AUTOSAR XML (schema 4-2-2)
package /STELLANTIS/EPT/ASWCs
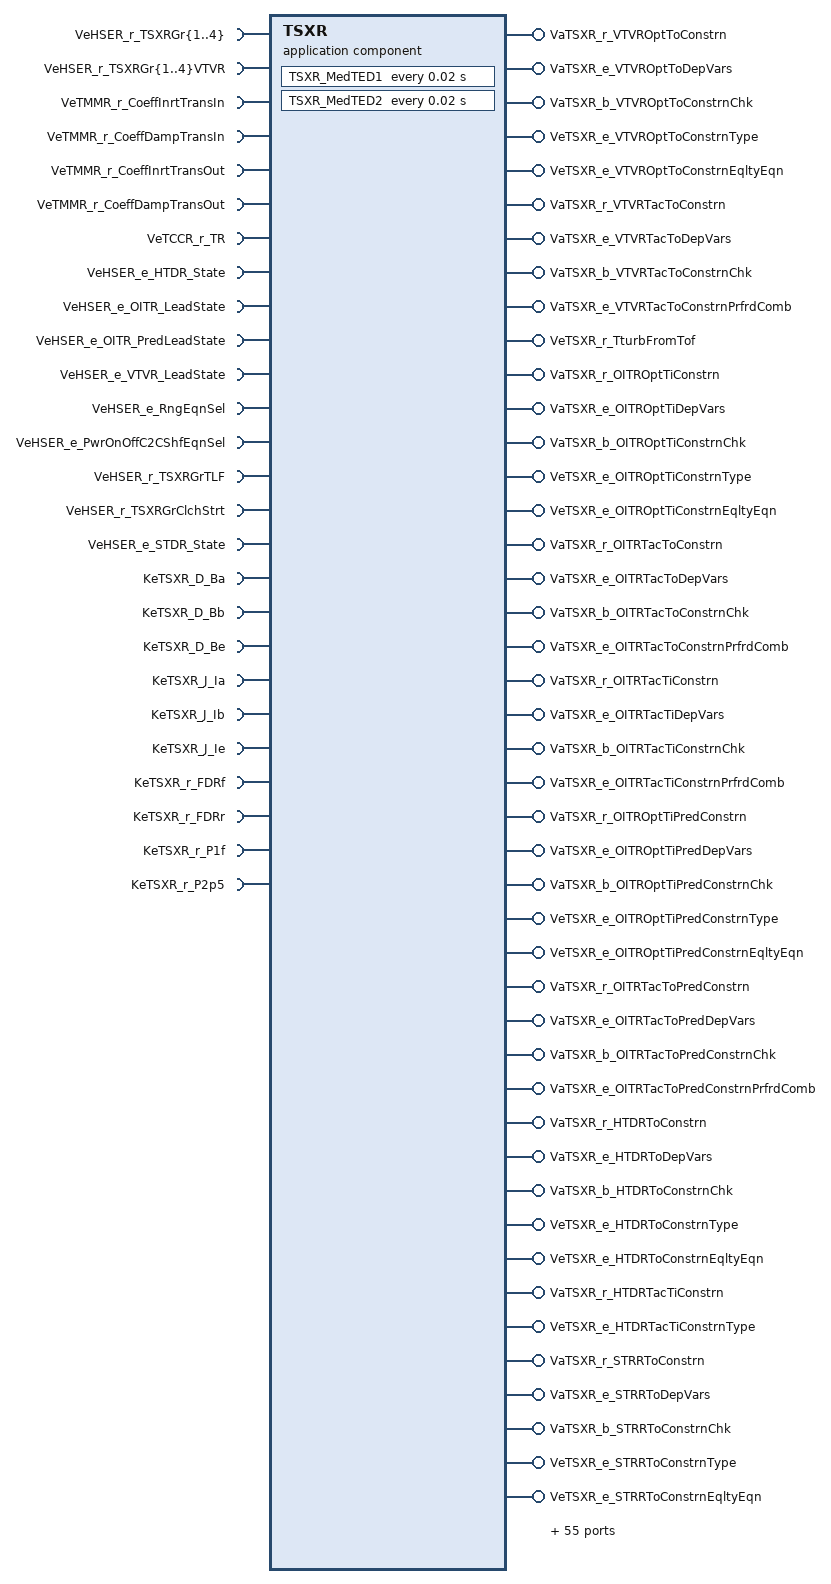
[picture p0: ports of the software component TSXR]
  application sw component type TSXR
    22 x require port:
      VeHSER_r_TSXRGr{1..4}: nonqueued-receiver-com-spec{data-element=Value, init-value=0}, required-interface=VeHSER_r_TSXRGr{1..4}
      VeHSER_r_TSXRGr{1..4}VTVR: nonqueued-receiver-com-spec{data-element=Value, init-value=0}, required-interface=VeHSER_r_TSXRGr{1..4}VTVR
      VeTMMR_r_CoeffInrtTransIn: nonqueued-receiver-com-spec{data-element=Value, init-value=0}, required-interface=VeTMMR_r_CoeffInrtTransIn
      VeTMMR_r_CoeffDampTransIn: nonqueued-receiver-com-spec{data-element=Value, init-value=0}, required-interface=VeTMMR_r_CoeffDampTransIn
      VeTMMR_r_CoeffInrtTransOut: nonqueued-receiver-com-spec{data-element=Value, init-value=0}, required-interface=VeTMMR_r_CoeffInrtTransOut
      VeTMMR_r_CoeffDampTransOut: nonqueued-receiver-com-spec{data-element=Value, init-value=0}, required-interface=VeTMMR_r_CoeffDampTransOut
      VeTCCR_r_TR: nonqueued-receiver-com-spec{data-element=Value, init-value=0}, required-interface=VeTCCR_r_TR
      VeHSER_e_HTDR_State: nonqueued-receiver-com-spec{data-element=Value, init-value=CeHSER_e_Neut_State}, required-interface=VeHSER_e_HTDR_State
      VeHSER_e_OITR_LeadState: nonqueued-receiver-com-spec{data-element=Value, init-value=CeHSER_e_Neut_State}, required-interface=VeHSER_e_OITR_LeadState
      VeHSER_e_OITR_PredLeadState: nonqueued-receiver-com-spec{data-element=Value, init-value=CeHSER_e_Neut_State}, required-interface=VeHSER_e_OITR_PredLeadState
      VeHSER_e_VTVR_LeadState: nonqueued-receiver-com-spec{data-element=Value, init-value=CeHSER_e_Neut_State}, required-interface=VeHSER_e_VTVR_LeadState
      VeHSER_e_RngEqnSel: nonqueued-receiver-com-spec{data-element=Value, init-value=CeHSER_e_UseNeutralEqn}, required-interface=VeHSER_e_RngEqnSel
      VeHSER_e_PwrOnOffC2CShfEqnSel: nonqueued-receiver-com-spec{data-element=Value, init-value=CeHSER_e_UseNeutralEqn}, required-interface=VeHSER_e_PwrOnOffC2CShfEqnSel
      VeHSER_r_TSXRGrTLF: nonqueued-receiver-com-spec{data-element=Value, init-value=0}, required-interface=VeHSER_r_TSXRGrTLF
      VeHSER_r_TSXRGrClchStrt: nonqueued-receiver-com-spec{data-element=Value, init-value=0}, required-interface=VeHSER_r_TSXRGrClchStrt
      VeHSER_e_STDR_State: nonqueued-receiver-com-spec{data-element=Value, init-value=CeHSER_e_Neut_State}, required-interface=VeHSER_e_STDR_State
    99 x provide port:
      VaTSXR_r_VTVROptToConstrn: nonqueued-sender-com-spec{data-element=Value, init-value=114 x 0}, provided-interface=VaTSXR_r_VTVROptToConstrn
      VaTSXR_e_VTVROptToDepVars: nonqueued-sender-com-spec{data-element=Value, init-value=6 x CeTSXR_e_Ta}, provided-interface=VaTSXR_e_VTVROptToDepVars
      VaTSXR_b_VTVROptToConstrnChk: nonqueued-sender-com-spec{data-element=Value, init-value=6 x 0}, provided-interface=VaTSXR_b_VTVROptToConstrnChk
      VeTSXR_e_VTVROptToConstrnType: nonqueued-sender-com-spec{data-element=Value, init-value=CeTSXR_e_Mode}, provided-interface=VeTSXR_e_VTVROptToConstrnType
      VeTSXR_e_VTVROptToConstrnEqltyEqn: nonqueued-sender-com-spec{data-element=Value, init-value=CeTSXR_e_Second}, provided-interface=VeTSXR_e_VTVROptToConstrnEqltyEqn
      VaTSXR_r_VTVRTacToConstrn: nonqueued-sender-com-spec{data-element=Value, init-value=114 x 0}, provided-interface=VaTSXR_r_VTVRTacToConstrn
      VaTSXR_e_VTVRTacToDepVars: nonqueued-sender-com-spec{data-element=Value, init-value=6 x CeTSXR_e_Ta}, provided-interface=VaTSXR_e_VTVRTacToDepVars
      VaTSXR_b_VTVRTacToConstrnChk: nonqueued-sender-com-spec{data-element=Value, init-value=6 x 0}, provided-interface=VaTSXR_b_VTVRTacToConstrnChk
      VaTSXR_e_VTVRTacToConstrnPrfrdComb: nonqueued-sender-com-spec{data-element=Value, init-value=10 x CeTSXR_e_NoComb}, provided-interface=VaTSXR_e_VTVRTacToConstrnPrfrdComb
      VeTSXR_r_TturbFromTof: nonqueued-sender-com-spec{data-element=Value, init-value=0}, provided-interface=VeTSXR_r_TturbFromTof
      VaTSXR_r_OITROptTiConstrn: nonqueued-sender-com-spec{data-element=Value, init-value=114 x 0}, provided-interface=VaTSXR_r_OITROptTiConstrn
      VaTSXR_e_OITROptTiDepVars: nonqueued-sender-com-spec{data-element=Value, init-value=6 x CeTSXR_e_Ta}, provided-interface=VaTSXR_e_OITROptTiDepVars
      VaTSXR_b_OITROptTiConstrnChk: nonqueued-sender-com-spec{data-element=Value, init-value=6 x 0}, provided-interface=VaTSXR_b_OITROptTiConstrnChk
      VeTSXR_e_OITROptTiConstrnType: nonqueued-sender-com-spec{data-element=Value, init-value=CeTSXR_e_Mode}, provided-interface=VeTSXR_e_OITROptTiConstrnType
      VeTSXR_e_OITROptTiConstrnEqltyEqn: nonqueued-sender-com-spec{data-element=Value, init-value=CeTSXR_e_Second}, provided-interface=VeTSXR_e_OITROptTiConstrnEqltyEqn
      VaTSXR_r_OITRTacToConstrn: nonqueued-sender-com-spec{data-element=Value, init-value=114 x 0}, provided-interface=VaTSXR_r_OITRTacToConstrn
      VaTSXR_e_OITRTacToDepVars: nonqueued-sender-com-spec{data-element=Value, init-value=6 x CeTSXR_e_Ta}, provided-interface=VaTSXR_e_OITRTacToDepVars
      VaTSXR_b_OITRTacToConstrnChk: nonqueued-sender-com-spec{data-element=Value, init-value=6 x 0}, provided-interface=VaTSXR_b_OITRTacToConstrnChk
      VaTSXR_e_OITRTacToConstrnPrfrdComb: nonqueued-sender-com-spec{data-element=Value, init-value=10 x CeTSXR_e_NoComb}, provided-interface=VaTSXR_e_OITRTacToConstrnPrfrdComb
      VaTSXR_r_OITRTacTiConstrn: nonqueued-sender-com-spec{data-element=Value, init-value=114 x 0}, provided-interface=VaTSXR_r_OITRTacTiConstrn
      VaTSXR_e_OITRTacTiDepVars: nonqueued-sender-com-spec{data-element=Value, init-value=6 x CeTSXR_e_Ta}, provided-interface=VaTSXR_e_OITRTacTiDepVars
      VaTSXR_b_OITRTacTiConstrnChk: nonqueued-sender-com-spec{data-element=Value, init-value=6 x 0}, provided-interface=VaTSXR_b_OITRTacTiConstrnChk
      VaTSXR_e_OITRTacTiConstrnPrfrdComb: nonqueued-sender-com-spec{data-element=Value, init-value=10 x CeTSXR_e_NoComb}, provided-interface=VaTSXR_e_OITRTacTiConstrnPrfrdComb
      VaTSXR_r_OITROptTiPredConstrn: nonqueued-sender-com-spec{data-element=Value, init-value=114 x 0}, provided-interface=VaTSXR_r_OITROptTiPredConstrn
      VaTSXR_e_OITROptTiPredDepVars: nonqueued-sender-com-spec{data-element=Value, init-value=6 x CeTSXR_e_Ta}, provided-interface=VaTSXR_e_OITROptTiPredDepVars
      VaTSXR_b_OITROptTiPredConstrnChk: nonqueued-sender-com-spec{data-element=Value, init-value=6 x 0}, provided-interface=VaTSXR_b_OITROptTiPredConstrnChk
      VeTSXR_e_OITROptTiPredConstrnType: nonqueued-sender-com-spec{data-element=Value, init-value=CeTSXR_e_Mode}, provided-interface=VeTSXR_e_OITROptTiPredConstrnType
      VeTSXR_e_OITROptTiPredConstrnEqltyEqn: nonqueued-sender-com-spec{data-element=Value, init-value=CeTSXR_e_Second}, provided-interface=VeTSXR_e_OITROptTiPredConstrnEqltyEqn
      VaTSXR_r_OITRTacToPredConstrn: nonqueued-sender-com-spec{data-element=Value, init-value=114 x 0}, provided-interface=VaTSXR_r_OITRTacToPredConstrn
      VaTSXR_e_OITRTacToPredDepVars: nonqueued-sender-com-spec{data-element=Value, init-value=6 x CeTSXR_e_Ta}, provided-interface=VaTSXR_e_OITRTacToPredDepVars
      VaTSXR_b_OITRTacToPredConstrnChk: nonqueued-sender-com-spec{data-element=Value, init-value=6 x 0}, provided-interface=VaTSXR_b_OITRTacToPredConstrnChk
      VaTSXR_e_OITRTacToPredConstrnPrfrdComb: nonqueued-sender-com-spec{data-element=Value, init-value=10 x CeTSXR_e_NoComb}, provided-interface=VaTSXR_e_OITRTacToPredConstrnPrfrdComb
      VaTSXR_r_HTDRToConstrn: nonqueued-sender-com-spec{data-element=Value, init-value=114 x 0}, provided-interface=VaTSXR_r_HTDRToConstrn
      VaTSXR_e_HTDRToDepVars: nonqueued-sender-com-spec{data-element=Value, init-value=6 x CeTSXR_e_Ta}, provided-interface=VaTSXR_e_HTDRToDepVars
      VaTSXR_b_HTDRToConstrnChk: nonqueued-sender-com-spec{data-element=Value, init-value=6 x 0}, provided-interface=VaTSXR_b_HTDRToConstrnChk
      VeTSXR_e_HTDRToConstrnType: nonqueued-sender-com-spec{data-element=Value, init-value=CeTSXR_e_Mode}, provided-interface=VeTSXR_e_HTDRToConstrnType
      VeTSXR_e_HTDRToConstrnEqltyEqn: nonqueued-sender-com-spec{data-element=Value, init-value=CeTSXR_e_Second}, provided-interface=VeTSXR_e_HTDRToConstrnEqltyEqn
      VaTSXR_r_HTDRTacTiConstrn: nonqueued-sender-com-spec{data-element=Value, init-value=114 x 0}, provided-interface=VaTSXR_r_HTDRTacTiConstrn
      VeTSXR_e_HTDRTacTiConstrnType: nonqueued-sender-com-spec{data-element=Value, init-value=CeTSXR_e_Mode}, provided-interface=VeTSXR_e_HTDRTacTiConstrnType
      VaTSXR_r_STRRToConstrn: nonqueued-sender-com-spec{data-element=Value, init-value=114 x 0}, provided-interface=VaTSXR_r_STRRToConstrn
      VaTSXR_e_STRRToDepVars: nonqueued-sender-com-spec{data-element=Value, init-value=6 x CeTSXR_e_Ta}, provided-interface=VaTSXR_e_STRRToDepVars
      VaTSXR_b_STRRToConstrnChk: nonqueued-sender-com-spec{data-element=Value, init-value=6 x 0}, provided-interface=VaTSXR_b_STRRToConstrnChk
      VeTSXR_e_STRRToConstrnType: nonqueued-sender-com-spec{data-element=Value, init-value=CeTSXR_e_Mode}, provided-interface=VeTSXR_e_STRRToConstrnType
      VeTSXR_e_STRRToConstrnEqltyEqn: nonqueued-sender-com-spec{data-element=Value, init-value=CeTSXR_e_Second}, provided-interface=VeTSXR_e_STRRToConstrnEqltyEqn
      VaTSXR_r_HSERNidotConstrn: nonqueued-sender-com-spec{data-element=Value, init-value=114 x 0}, provided-interface=VaTSXR_r_HSERNidotConstrn
      VaTSXR_e_HSERNidotDepVars: nonqueued-sender-com-spec{data-element=Value, init-value=6 x CeTSXR_e_Ta}, provided-interface=VaTSXR_e_HSERNidotDepVars
      VaTSXR_b_HSERNidotConstrnChk: nonqueued-sender-com-spec{data-element=Value, init-value=6 x 0}, provided-interface=VaTSXR_b_HSERNidotConstrnChk
      VaTSXR_e_HSERNidotConstrnPrfrdComb: nonqueued-sender-com-spec{data-element=Value, init-value=10 x CeTSXR_e_NoComb}, provided-interface=VaTSXR_e_HSERNidotConstrnPrfrdComb
      VaTSXR_r_HSERNxDotCnstrnt: nonqueued-sender-com-spec{data-element=Value, init-value=114 x 0}, provided-interface=VaTSXR_r_HSERNxDotCnstrnt
      VaTSXR_e_HSERNxDotDepVars: nonqueued-sender-com-spec{data-element=Value, init-value=6 x CeTSXR_e_Ta}, provided-interface=VaTSXR_e_HSERNxDotDepVars
      VaTSXR_b_HSERNxDotChk: nonqueued-sender-com-spec{data-element=Value, init-value=6 x 0}, provided-interface=VaTSXR_b_HSERNxDotChk
      VaTSXR_e_HSERNxdotConstrnPrfrdComb: nonqueued-sender-com-spec{data-element=Value, init-value=10 x CeTSXR_e_NoComb}, provided-interface=VaTSXR_e_HSERNxdotConstrnPrfrdComb
      VaTSXR_r_HSERTcyFromTcxAndTi_TaTbDep: nonqueued-sender-com-spec{data-element=Value, init-value=[0, 0]}, provided-interface=VaTSXR_r_HSERTcyFromTcxAndTi_TaTbDep
      VaTSXR_r_AXLRCalcToEqn: nonqueued-sender-com-spec{data-element=Value, init-value=19 x 0}, provided-interface=VaTSXR_r_AXLRCalcToEqn
      VaTSXR_r_TITRCalcTiEqn: nonqueued-sender-com-spec{data-element=Value, init-value=19 x 0}, provided-interface=VaTSXR_r_TITRCalcTiEqn
      VaTSXR_r_HSERNiMat: nonqueued-sender-com-spec{data-element=Value, init-value=36 x 0}, provided-interface=VaTSXR_r_HSERNiMat
      VaTSXR_b_HSERNiMatChk: nonqueued-sender-com-spec{data-element=Value, init-value=[0, 0, 0, 0]}, provided-interface=VaTSXR_b_HSERNiMatChk
      VaTSXR_b_HSERNiMatActSpdFlag: nonqueued-sender-com-spec{data-element=Value, init-value=9 x 0}, provided-interface=VaTSXR_b_HSERNiMatActSpdFlag
      VaTSXR_r_HSERNoMat: nonqueued-sender-com-spec{data-element=Value, init-value=36 x 0}, provided-interface=VaTSXR_r_HSERNoMat
      VaTSXR_b_HSERNoMatChk: nonqueued-sender-com-spec{data-element=Value, init-value=[0, 0, 0, 0]}, provided-interface=VaTSXR_b_HSERNoMatChk
      VaTSXR_b_HSERNoMatActSpdFlag: nonqueued-sender-com-spec{data-element=Value, init-value=9 x 0}, provided-interface=VaTSXR_b_HSERNoMatActSpdFlag
      VaTSXR_r_STDRMotSpdMat_NmDep: nonqueued-sender-com-spec{data-element=Value, init-value=9 x 0}, provided-interface=VaTSXR_r_STDRMotSpdMat_NmDep
      VaTSXR_r_OITRMotSpdMat_NmDep: nonqueued-sender-com-spec{data-element=Value, init-value=9 x 0}, provided-interface=VaTSXR_r_OITRMotSpdMat_NmDep
      VaTSXR_r_VTVRMotSpdMat_NmDep: nonqueued-sender-com-spec{data-element=Value, init-value=9 x 0}, provided-interface=VaTSXR_r_VTVRMotSpdMat_NmDep
      VaTSXR_r_N_ClchSlpMat_NcnDep: nonqueued-sender-com-spec{data-element=Value, init-value=32 x 0}, provided-interface=VaTSXR_r_N_ClchSlpMat_NcnDep
      VaTSXR_r_M1_ClchSlpMat_NcnDep: nonqueued-sender-com-spec{data-element=Value, init-value=32 x 0}, provided-interface=VaTSXR_r_M1_ClchSlpMat_NcnDep
      VaTSXR_r_M2_ClchSlpMat_NcnDep: nonqueued-sender-com-spec{data-element=Value, init-value=32 x 0}, provided-interface=VaTSXR_r_M2_ClchSlpMat_NcnDep
      VaTSXR_r_GearRatios: nonqueued-sender-com-spec{data-element=Value, init-value=[0, 0, 0, 0]}, provided-interface=VaTSXR_r_GearRatios
      VaTSXR_r_M_CalcTCxEqn: nonqueued-sender-com-spec{data-element=Value, init-value=76 x 0}, provided-interface=VaTSXR_r_M_CalcTCxEqn
      VaTSXR_r_CalcTlfEqn: nonqueued-sender-com-spec{data-element=Value, init-value=19 x 0}, provided-interface=VaTSXR_r_CalcTlfEqn
      VaTSXR_r_STRRNxMat_NcnDep: nonqueued-sender-com-spec{data-element=Value, init-value=6 x 0}, provided-interface=VaTSXR_r_STRRNxMat_NcnDep
      VaTSXR_r_HSERNxMat: nonqueued-sender-com-spec{data-element=Value, init-value=36 x 0}, provided-interface=VaTSXR_r_HSERNxMat
      VaTSXR_b_HSERNxMatChk: nonqueued-sender-com-spec{data-element=Value, init-value=[0, 0, 0, 0]}, provided-interface=VaTSXR_b_HSERNxMatChk
      VaTSXR_b_HSERNxMatActSpdFlag: nonqueued-sender-com-spec{data-element=Value, init-value=9 x 0}, provided-interface=VaTSXR_b_HSERNxMatActSpdFlag
      VaTSXR_r_HSERNxNc1IndDep: nonqueued-sender-com-spec{data-element=Value, init-value=12 x 0}, provided-interface=VaTSXR_r_HSERNxNc1IndDep
      VaTSXR_r_HSERNxNc2IndDep: nonqueued-sender-com-spec{data-element=Value, init-value=12 x 0}, provided-interface=VaTSXR_r_HSERNxNc2IndDep
      VaTSXR_r_HSERNxNMtrIndDep: nonqueued-sender-com-spec{data-element=Value, init-value=12 x 0}, provided-interface=VaTSXR_r_HSERNxNMtrIndDep
      VeTSXR_r_NoDot2NxDot: nonqueued-sender-com-spec{data-element=Value, init-value=0}, provided-interface=VeTSXR_r_NoDot2NxDot
      VeTSXR_e_VTVRTacToConstrnCombEqn: nonqueued-sender-com-spec{data-element=Value, init-value=CeTSXR_e_Second}, provided-interface=VeTSXR_e_VTVRTacToConstrnCombEqn
      VeTSXR_e_OITRTacTiConstrnCombEqn: nonqueued-sender-com-spec{data-element=Value, init-value=CeTSXR_e_Second}, provided-interface=VeTSXR_e_OITRTacTiConstrnCombEqn
      VeTSXR_e_HSERNidotConstrnCombEqn: nonqueued-sender-com-spec{data-element=Value, init-value=CeTSXR_e_Second}, provided-interface=VeTSXR_e_HSERNidotConstrnCombEqn
      VeTSXR_e_OITRTacToPredConstrnCombEqn: nonqueued-sender-com-spec{data-element=Value, init-value=CeTSXR_e_Second}, provided-interface=VeTSXR_e_OITRTacToPredConstrnCombEqn
      VeTSXR_e_OITRTacToConstrnCombEqn: nonqueued-sender-com-spec{data-element=Value, init-value=CeTSXR_e_Second}, provided-interface=VeTSXR_e_OITRTacToConstrnCombEqn
      VeTSXR_e_HSERNxdotConstrnCombEqn: nonqueued-sender-com-spec{data-element=Value, init-value=CeTSXR_e_Second}, provided-interface=VeTSXR_e_HSERNxdotConstrnCombEqn
      VaTSXR_r_AXLRCalcTofEqn: nonqueued-sender-com-spec{data-element=Value, init-value=19 x 0}, provided-interface=VaTSXR_r_AXLRCalcTofEqn
      VaTSXR_r_AXLRCalcTorEqn: nonqueued-sender-com-spec{data-element=Value, init-value=19 x 0}, provided-interface=VaTSXR_r_AXLRCalcTorEqn
      VaTSXR_b_VTVRToConstrnPalChk: nonqueued-sender-com-spec{data-element=Value, init-value=6 x 0}, provided-interface=VaTSXR_b_VTVRToConstrnPalChk
      VaTSXR_b_OITRTacToPredConstrnPalChk: nonqueued-sender-com-spec{data-element=Value, init-value=6 x 0}, provided-interface=VaTSXR_b_OITRTacToPredConstrnPalChk
      VaTSXR_b_OITRTacToConstrnPalChk: nonqueued-sender-com-spec{data-element=Value, init-value=6 x 0}, provided-interface=VaTSXR_b_OITRTacToConstrnPalChk
      VaTSXR_b_OITRTacTiConstrnPalChk: nonqueued-sender-com-spec{data-element=Value, init-value=6 x 0}, provided-interface=VaTSXR_b_OITRTacTiConstrnPalChk
      VaTSXR_b_HTDRTacTiConstrnPalChk: nonqueued-sender-com-spec{data-element=Value, init-value=6 x 0}, provided-interface=VaTSXR_b_HTDRTacTiConstrnPalChk
      VaTSXR_b_HSERNidotConstrnPalChk: nonqueued-sender-com-spec{data-element=Value, init-value=6 x 0}, provided-interface=VaTSXR_b_HSERNidotConstrnPalChk
      VaTSXR_b_HSERNxdotConstrnPalChk: nonqueued-sender-com-spec{data-element=Value, init-value=6 x 0}, provided-interface=VaTSXR_b_HSERNxdotConstrnPalChk
      VaTSXR_r_OITRTacTiPredConstrn: nonqueued-sender-com-spec{data-element=Value, init-value=114 x 0}, provided-interface=VaTSXR_r_OITRTacTiPredConstrn
      VaTSXR_e_OITRTacTiPredDepVars: nonqueued-sender-com-spec{data-element=Value, init-value=6 x CeTSXR_e_Ta}, provided-interface=VaTSXR_e_OITRTacTiPredDepVars
      VaTSXR_b_OITRTacTiPredConstrnChk: nonqueued-sender-com-spec{data-element=Value, init-value=6 x 0}, provided-interface=VaTSXR_b_OITRTacTiPredConstrnChk
      VaTSXR_e_OITRTacTiPredConstrnPrfrdComb: nonqueued-sender-com-spec{data-element=Value, init-value=10 x CeTSXR_e_NoComb}, provided-interface=VaTSXR_e_OITRTacTiPredConstrnPrfrdComb
      VeTSXR_e_OITRTacTiPredConstrnCombEqn: nonqueued-sender-com-spec{data-element=Value, init-value=CeTSXR_e_Second}, provided-interface=VeTSXR_e_OITRTacTiPredConstrnCombEqn
      VaTSXR_b_OITRTacTiPredConstrnPalChk: nonqueued-sender-com-spec{data-element=Value, init-value=6 x 0}, provided-interface=VaTSXR_b_OITRTacTiPredConstrnPalChk
    10 x require port:
      KeTSXR_D_Ba: parameter-require-com-spec{init-value=KeTSXR_D_Ba_KeTSXR_D_Ba:0.000165328965522349, parameter=KeTSXR_D_Ba}, required-interface=KeTSXR_D_Ba
      KeTSXR_D_Bb: parameter-require-com-spec{init-value=KeTSXR_D_Bb_KeTSXR_D_Bb:5.01592949149199E-05, parameter=KeTSXR_D_Bb}, required-interface=KeTSXR_D_Bb
      KeTSXR_D_Be: parameter-require-com-spec{init-value=KeTSXR_D_Be_KeTSXR_D_Be:0.00143155723344535, parameter=KeTSXR_D_Be}, required-interface=KeTSXR_D_Be
      KeTSXR_J_Ia: parameter-require-com-spec{init-value=KeTSXR_J_Ia_KeTSXR_J_Ia:0.00136836851015687, parameter=KeTSXR_J_Ia}, required-interface=KeTSXR_J_Ia
      KeTSXR_J_Ib: parameter-require-com-spec{init-value=KeTSXR_J_Ib_KeTSXR_J_Ib:0.0059690261259675026, parameter=KeTSXR_J_Ib}, required-interface=KeTSXR_J_Ib
      KeTSXR_J_Ie: parameter-require-com-spec{init-value=KeTSXR_J_Ie_KeTSXR_J_Ie:0.0124616511166096, parameter=KeTSXR_J_Ie}, required-interface=KeTSXR_J_Ie
      KeTSXR_r_FDRf: parameter-require-com-spec{init-value=KeTSXR_r_FDRf_KeTSXR_r_FDRf:3.58823537826538, parameter=KeTSXR_r_FDRf}, required-interface=KeTSXR_r_FDRf
      KeTSXR_r_FDRr: parameter-require-com-spec{init-value=KeTSXR_r_FDRr_KeTSXR_r_FDRr:11.1999998092651, parameter=KeTSXR_r_FDRr}, required-interface=KeTSXR_r_FDRr
      KeTSXR_r_P1f: parameter-require-com-spec{init-value=KeTSXR_r_P1f_KeTSXR_r_P1f:2.55550003051758, parameter=KeTSXR_r_P1f}, required-interface=KeTSXR_r_P1f
      KeTSXR_r_P2p5: parameter-require-com-spec{init-value=KeTSXR_r_P2p5_KeTSXR_r_P2p5:2.5, parameter=KeTSXR_r_P2p5}, required-interface=KeTSXR_r_P2p5
    behavior IB_TSXR: data-type-mapping=msADTtoIDTMapping, handle-termination-and-restart=NO-SUPPORT
      timing event Event_MedTED1: start-on-event=TSXR_MedTED1, period=0.02
      timing event Event_MedTED2: start-on-event=TSXR_MedTED2, period=0.02
      init event Event_TSXR_ac_Init: start-on-event=TSXR_ac_Init
      init event Event_PwrOn: start-on-event=TSXR_PwrOn
      4 x runnable:
        TSXR_ac_Init
          data-send-points:
            97 x access:
              OUT_VaTSXR_r_VTVROptToConstrn_Value: accessed-variable=VaTSXR_r_VTVROptToConstrn.Value
              OUT_VaTSXR_e_VTVROptToDepVars_Value: accessed-variable=VaTSXR_e_VTVROptToDepVars.Value
              OUT_VaTSXR_b_VTVROptToConstrnChk_Value: accessed-variable=VaTSXR_b_VTVROptToConstrnChk.Value
              OUT_VeTSXR_e_VTVROptToConstrnType_Value: accessed-variable=VeTSXR_e_VTVROptToConstrnType.Value
              OUT_VeTSXR_e_VTVROptToConstrnEqltyEqn_Value: accessed-variable=VeTSXR_e_VTVROptToConstrnEqltyEqn.Value
              OUT_VaTSXR_r_VTVRTacToConstrn_Value: accessed-variable=VaTSXR_r_VTVRTacToConstrn.Value
              OUT_VaTSXR_e_VTVRTacToDepVars_Value: accessed-variable=VaTSXR_e_VTVRTacToDepVars.Value
              OUT_VaTSXR_b_VTVRTacToConstrnChk_Value: accessed-variable=VaTSXR_b_VTVRTacToConstrnChk.Value
              OUT_VaTSXR_e_VTVRTacToConstrnPrfrdComb_Value: accessed-variable=VaTSXR_e_VTVRTacToConstrnPrfrdComb.Value
              OUT_VaTSXR_r_OITROptTiConstrn_Value: accessed-variable=VaTSXR_r_OITROptTiConstrn.Value
              OUT_VaTSXR_e_OITROptTiDepVars_Value: accessed-variable=VaTSXR_e_OITROptTiDepVars.Value
              OUT_VaTSXR_b_OITROptTiConstrnChk_Value: accessed-variable=VaTSXR_b_OITROptTiConstrnChk.Value
              OUT_VeTSXR_e_OITROptTiConstrnType_Value: accessed-variable=VeTSXR_e_OITROptTiConstrnType.Value
              OUT_VeTSXR_e_OITROptTiConstrnEqltyEqn_Value: accessed-variable=VeTSXR_e_OITROptTiConstrnEqltyEqn.Value
              OUT_VaTSXR_r_OITRTacToConstrn_Value: accessed-variable=VaTSXR_r_OITRTacToConstrn.Value
              OUT_VaTSXR_e_OITRTacToDepVars_Value: accessed-variable=VaTSXR_e_OITRTacToDepVars.Value
              OUT_VaTSXR_b_OITRTacToConstrnChk_Value: accessed-variable=VaTSXR_b_OITRTacToConstrnChk.Value
              OUT_VaTSXR_e_OITRTacToConstrnPrfrdComb_Value: accessed-variable=VaTSXR_e_OITRTacToConstrnPrfrdComb.Value
              OUT_VaTSXR_r_OITRTacTiConstrn_Value: accessed-variable=VaTSXR_r_OITRTacTiConstrn.Value
              OUT_VaTSXR_e_OITRTacTiDepVars_Value: accessed-variable=VaTSXR_e_OITRTacTiDepVars.Value
              OUT_VaTSXR_b_OITRTacTiConstrnChk_Value: accessed-variable=VaTSXR_b_OITRTacTiConstrnChk.Value
              OUT_VaTSXR_e_OITRTacTiConstrnPrfrdComb_Value: accessed-variable=VaTSXR_e_OITRTacTiConstrnPrfrdComb.Value
              OUT_VaTSXR_r_OITROptTiPredConstrn_Value: accessed-variable=VaTSXR_r_OITROptTiPredConstrn.Value
              OUT_VaTSXR_e_OITROptTiPredDepVars_Value: accessed-variable=VaTSXR_e_OITROptTiPredDepVars.Value
              OUT_VaTSXR_b_OITROptTiPredConstrnChk_Value: accessed-variable=VaTSXR_b_OITROptTiPredConstrnChk.Value
              OUT_VeTSXR_e_OITROptTiPredConstrnType_Value: accessed-variable=VeTSXR_e_OITROptTiPredConstrnType.Value
              OUT_VeTSXR_e_OITROptTiPredConstrnEqltyEqn_Value: accessed-variable=VeTSXR_e_OITROptTiPredConstrnEqltyEqn.Value
              OUT_VaTSXR_r_OITRTacToPredConstrn_Value: accessed-variable=VaTSXR_r_OITRTacToPredConstrn.Value
              OUT_VaTSXR_e_OITRTacToPredDepVars_Value: accessed-variable=VaTSXR_e_OITRTacToPredDepVars.Value
              OUT_VaTSXR_b_OITRTacToPredConstrnChk_Value: accessed-variable=VaTSXR_b_OITRTacToPredConstrnChk.Value
              OUT_VaTSXR_e_OITRTacToPredConstrnPrfrdComb_Value: accessed-variable=VaTSXR_e_OITRTacToPredConstrnPrfrdComb.Value
              OUT_VaTSXR_r_HTDRToConstrn_Value: accessed-variable=VaTSXR_r_HTDRToConstrn.Value
              OUT_VaTSXR_e_HTDRToDepVars_Value: accessed-variable=VaTSXR_e_HTDRToDepVars.Value
              OUT_VaTSXR_b_HTDRToConstrnChk_Value: accessed-variable=VaTSXR_b_HTDRToConstrnChk.Value
              OUT_VeTSXR_e_HTDRToConstrnType_Value: accessed-variable=VeTSXR_e_HTDRToConstrnType.Value
              OUT_VeTSXR_e_HTDRToConstrnEqltyEqn_Value: accessed-variable=VeTSXR_e_HTDRToConstrnEqltyEqn.Value
              OUT_VaTSXR_r_HTDRTacTiConstrn_Value: accessed-variable=VaTSXR_r_HTDRTacTiConstrn.Value
              OUT_VeTSXR_e_HTDRTacTiConstrnType_Value: accessed-variable=VeTSXR_e_HTDRTacTiConstrnType.Value
              OUT_VaTSXR_r_STRRToConstrn_Value: accessed-variable=VaTSXR_r_STRRToConstrn.Value
              OUT_VaTSXR_e_STRRToDepVars_Value: accessed-variable=VaTSXR_e_STRRToDepVars.Value
              OUT_VaTSXR_b_STRRToConstrnChk_Value: accessed-variable=VaTSXR_b_STRRToConstrnChk.Value
              OUT_VeTSXR_e_STRRToConstrnType_Value: accessed-variable=VeTSXR_e_STRRToConstrnType.Value
              OUT_VeTSXR_e_STRRToConstrnEqltyEqn_Value: accessed-variable=VeTSXR_e_STRRToConstrnEqltyEqn.Value
              OUT_VaTSXR_r_HSERNidotConstrn_Value: accessed-variable=VaTSXR_r_HSERNidotConstrn.Value
              OUT_VaTSXR_e_HSERNidotDepVars_Value: accessed-variable=VaTSXR_e_HSERNidotDepVars.Value
              OUT_VaTSXR_b_HSERNidotConstrnChk_Value: accessed-variable=VaTSXR_b_HSERNidotConstrnChk.Value
              OUT_VaTSXR_e_HSERNidotConstrnPrfrdComb_Value: accessed-variable=VaTSXR_e_HSERNidotConstrnPrfrdComb.Value
              OUT_VaTSXR_r_HSERNxDotCnstrnt_Value: accessed-variable=VaTSXR_r_HSERNxDotCnstrnt.Value
              OUT_VaTSXR_e_HSERNxDotDepVars_Value: accessed-variable=VaTSXR_e_HSERNxDotDepVars.Value
              OUT_VaTSXR_b_HSERNxDotChk_Value: accessed-variable=VaTSXR_b_HSERNxDotChk.Value
              OUT_VaTSXR_e_HSERNxdotConstrnPrfrdComb_Value: accessed-variable=VaTSXR_e_HSERNxdotConstrnPrfrdComb.Value
              OUT_VaTSXR_r_HSERTcyFromTcxAndTi_TaTbDep_Value: accessed-variable=VaTSXR_r_HSERTcyFromTcxAndTi_TaTbDep.Value
              OUT_VaTSXR_r_AXLRCalcToEqn_Value: accessed-variable=VaTSXR_r_AXLRCalcToEqn.Value
              OUT_VaTSXR_r_TITRCalcTiEqn_Value: accessed-variable=VaTSXR_r_TITRCalcTiEqn.Value
              OUT_VaTSXR_r_HSERNiMat_Value: accessed-variable=VaTSXR_r_HSERNiMat.Value
              OUT_VaTSXR_b_HSERNiMatChk_Value: accessed-variable=VaTSXR_b_HSERNiMatChk.Value
              OUT_VaTSXR_b_HSERNiMatActSpdFlag_Value: accessed-variable=VaTSXR_b_HSERNiMatActSpdFlag.Value
              OUT_VaTSXR_r_HSERNoMat_Value: accessed-variable=VaTSXR_r_HSERNoMat.Value
              OUT_VaTSXR_b_HSERNoMatChk_Value: accessed-variable=VaTSXR_b_HSERNoMatChk.Value
              OUT_VaTSXR_b_HSERNoMatActSpdFlag_Value: accessed-variable=VaTSXR_b_HSERNoMatActSpdFlag.Value
              OUT_VaTSXR_r_STDRMotSpdMat_NmDep_Value: accessed-variable=VaTSXR_r_STDRMotSpdMat_NmDep.Value
              OUT_VaTSXR_r_OITRMotSpdMat_NmDep_Value: accessed-variable=VaTSXR_r_OITRMotSpdMat_NmDep.Value
              OUT_VaTSXR_r_VTVRMotSpdMat_NmDep_Value: accessed-variable=VaTSXR_r_VTVRMotSpdMat_NmDep.Value
              OUT_VaTSXR_r_N_ClchSlpMat_NcnDep_Value: accessed-variable=VaTSXR_r_N_ClchSlpMat_NcnDep.Value
              OUT_VaTSXR_r_M1_ClchSlpMat_NcnDep_Value: accessed-variable=VaTSXR_r_M1_ClchSlpMat_NcnDep.Value
              OUT_VaTSXR_r_M2_ClchSlpMat_NcnDep_Value: accessed-variable=VaTSXR_r_M2_ClchSlpMat_NcnDep.Value
              OUT_VaTSXR_r_GearRatios_Value: accessed-variable=VaTSXR_r_GearRatios.Value
              OUT_VaTSXR_r_M_CalcTCxEqn_Value: accessed-variable=VaTSXR_r_M_CalcTCxEqn.Value
              OUT_VaTSXR_r_CalcTlfEqn_Value: accessed-variable=VaTSXR_r_CalcTlfEqn.Value
              OUT_VaTSXR_r_STRRNxMat_NcnDep_Value: accessed-variable=VaTSXR_r_STRRNxMat_NcnDep.Value
              OUT_VaTSXR_r_HSERNxMat_Value: accessed-variable=VaTSXR_r_HSERNxMat.Value
              OUT_VaTSXR_b_HSERNxMatChk_Value: accessed-variable=VaTSXR_b_HSERNxMatChk.Value
              OUT_VaTSXR_b_HSERNxMatActSpdFlag_Value: accessed-variable=VaTSXR_b_HSERNxMatActSpdFlag.Value
              OUT_VaTSXR_r_HSERNxNc1IndDep_Value: accessed-variable=VaTSXR_r_HSERNxNc1IndDep.Value
              OUT_VaTSXR_r_HSERNxNc2IndDep_Value: accessed-variable=VaTSXR_r_HSERNxNc2IndDep.Value
              OUT_VaTSXR_r_HSERNxNMtrIndDep_Value: accessed-variable=VaTSXR_r_HSERNxNMtrIndDep.Value
              OUT_VeTSXR_e_VTVRTacToConstrnCombEqn_Value: accessed-variable=VeTSXR_e_VTVRTacToConstrnCombEqn.Value
              OUT_VeTSXR_e_OITRTacTiConstrnCombEqn_Value: accessed-variable=VeTSXR_e_OITRTacTiConstrnCombEqn.Value
              OUT_VeTSXR_e_HSERNidotConstrnCombEqn_Value: accessed-variable=VeTSXR_e_HSERNidotConstrnCombEqn.Value
              OUT_VeTSXR_e_OITRTacToPredConstrnCombEqn_Value: accessed-variable=VeTSXR_e_OITRTacToPredConstrnCombEqn.Value
              OUT_VeTSXR_e_OITRTacToConstrnCombEqn_Value: accessed-variable=VeTSXR_e_OITRTacToConstrnCombEqn.Value
              OUT_VeTSXR_e_HSERNxdotConstrnCombEqn_Value: accessed-variable=VeTSXR_e_HSERNxdotConstrnCombEqn.Value
              OUT_VaTSXR_r_AXLRCalcTofEqn_Value: accessed-variable=VaTSXR_r_AXLRCalcTofEqn.Value
              OUT_VaTSXR_r_AXLRCalcTorEqn_Value: accessed-variable=VaTSXR_r_AXLRCalcTorEqn.Value
              OUT_VaTSXR_b_VTVRToConstrnPalChk_Value: accessed-variable=VaTSXR_b_VTVRToConstrnPalChk.Value
              OUT_VaTSXR_b_OITRTacToPredConstrnPalChk_Value: accessed-variable=VaTSXR_b_OITRTacToPredConstrnPalChk.Value
              OUT_VaTSXR_b_OITRTacToConstrnPalChk_Value: accessed-variable=VaTSXR_b_OITRTacToConstrnPalChk.Value
              OUT_VaTSXR_b_OITRTacTiConstrnPalChk_Value: accessed-variable=VaTSXR_b_OITRTacTiConstrnPalChk.Value
              OUT_VaTSXR_b_HTDRTacTiConstrnPalChk_Value: accessed-variable=VaTSXR_b_HTDRTacTiConstrnPalChk.Value
              OUT_VaTSXR_b_HSERNidotConstrnPalChk_Value: accessed-variable=VaTSXR_b_HSERNidotConstrnPalChk.Value
              OUT_VaTSXR_b_HSERNxdotConstrnPalChk_Value: accessed-variable=VaTSXR_b_HSERNxdotConstrnPalChk.Value
              OUT_VaTSXR_r_OITRTacTiPredConstrn_Value: accessed-variable=VaTSXR_r_OITRTacTiPredConstrn.Value
              OUT_VaTSXR_e_OITRTacTiPredDepVars_Value: accessed-variable=VaTSXR_e_OITRTacTiPredDepVars.Value
              OUT_VaTSXR_b_OITRTacTiPredConstrnChk_Value: accessed-variable=VaTSXR_b_OITRTacTiPredConstrnChk.Value
              OUT_VaTSXR_e_OITRTacTiPredConstrnPrfrdComb_Value: accessed-variable=VaTSXR_e_OITRTacTiPredConstrnPrfrdComb.Value
              OUT_VeTSXR_e_OITRTacTiPredConstrnCombEqn_Value: accessed-variable=VeTSXR_e_OITRTacTiPredConstrnCombEqn.Value
              OUT_VaTSXR_b_OITRTacTiPredConstrnPalChk_Value: accessed-variable=VaTSXR_b_OITRTacTiPredConstrnPalChk.Value
        TSXR_MedTED1
          data-receive-point-by-arguments:
            5 x access:
              IN_VeHSER_r_TSXRGr{1..4}_Value: accessed-variable=VeHSER_r_TSXRGr{1..4}.Value
              IN_VeTCCR_r_TR_Value: accessed-variable=VeTCCR_r_TR.Value
          data-send-points:
            5 x access:
              OUT_VaTSXR_r_N_ClchSlpMat_NcnDep_Value: accessed-variable=VaTSXR_r_N_ClchSlpMat_NcnDep.Value
              OUT_VaTSXR_r_M1_ClchSlpMat_NcnDep_Value: accessed-variable=VaTSXR_r_M1_ClchSlpMat_NcnDep.Value
              OUT_VaTSXR_r_M2_ClchSlpMat_NcnDep_Value: accessed-variable=VaTSXR_r_M2_ClchSlpMat_NcnDep.Value
              OUT_VaTSXR_r_GearRatios_Value: accessed-variable=VaTSXR_r_GearRatios.Value
              OUT_VaTSXR_r_STRRNxMat_NcnDep_Value: accessed-variable=VaTSXR_r_STRRNxMat_NcnDep.Value
          parameter access CALPRM_KeTSXR_r_FDRf_KeTSXR_r_FDRf: accessed-parameter=KeTSXR_r_FDRf.KeTSXR_r_FDRf
          parameter access CALPRM_KeTSXR_r_FDRr_KeTSXR_r_FDRr: accessed-parameter=KeTSXR_r_FDRr.KeTSXR_r_FDRr
          parameter access CALPRM_KeTSXR_r_P2p5_KeTSXR_r_P2p5: accessed-parameter=KeTSXR_r_P2p5.KeTSXR_r_P2p5
        TSXR_MedTED2
          data-receive-point-by-arguments:
            22 x access:
              IN_VeHSER_e_HTDR_State_Value: accessed-variable=VeHSER_e_HTDR_State.Value
              IN_VeHSER_e_OITR_LeadState_Value: accessed-variable=VeHSER_e_OITR_LeadState.Value
              IN_VeHSER_e_OITR_PredLeadState_Value: accessed-variable=VeHSER_e_OITR_PredLeadState.Value
              IN_VeHSER_e_PwrOnOffC2CShfEqnSel_Value: accessed-variable=VeHSER_e_PwrOnOffC2CShfEqnSel.Value
              IN_VeHSER_e_RngEqnSel_Value: accessed-variable=VeHSER_e_RngEqnSel.Value
              IN_VeHSER_e_STDR_State_Value: accessed-variable=VeHSER_e_STDR_State.Value
              IN_VeHSER_e_VTVR_LeadState_Value: accessed-variable=VeHSER_e_VTVR_LeadState.Value
              IN_VeHSER_r_TSXRGr1_Value: accessed-variable=VeHSER_r_TSXRGr1.Value
              IN_VeHSER_r_TSXRGr1VTVR_Value: accessed-variable=VeHSER_r_TSXRGr1VTVR.Value
              IN_VeHSER_r_TSXRGr2_Value: accessed-variable=VeHSER_r_TSXRGr2.Value
              IN_VeHSER_r_TSXRGr2VTVR_Value: accessed-variable=VeHSER_r_TSXRGr2VTVR.Value
              IN_VeHSER_r_TSXRGr3_Value: accessed-variable=VeHSER_r_TSXRGr3.Value
              IN_VeHSER_r_TSXRGr3VTVR_Value: accessed-variable=VeHSER_r_TSXRGr3VTVR.Value
              IN_VeHSER_r_TSXRGr4_Value: accessed-variable=VeHSER_r_TSXRGr4.Value
              IN_VeHSER_r_TSXRGr4VTVR_Value: accessed-variable=VeHSER_r_TSXRGr4VTVR.Value
              IN_VeHSER_r_TSXRGrClchStrt_Value: accessed-variable=VeHSER_r_TSXRGrClchStrt.Value
              IN_VeHSER_r_TSXRGrTLF_Value: accessed-variable=VeHSER_r_TSXRGrTLF.Value
              IN_VeTCCR_r_TR_Value: accessed-variable=VeTCCR_r_TR.Value
              IN_VeTMMR_r_CoeffDampTransIn_Value: accessed-variable=VeTMMR_r_CoeffDampTransIn.Value
              IN_VeTMMR_r_CoeffDampTransOut_Value: accessed-variable=VeTMMR_r_CoeffDampTransOut.Value
              IN_VeTMMR_r_CoeffInrtTransIn_Value: accessed-variable=VeTMMR_r_CoeffInrtTransIn.Value
              IN_VeTMMR_r_CoeffInrtTransOut_Value: accessed-variable=VeTMMR_r_CoeffInrtTransOut.Value
          data-send-points:
            94 x access:
              OUT_VaTSXR_r_VTVROptToConstrn_Value: accessed-variable=VaTSXR_r_VTVROptToConstrn.Value
              OUT_VaTSXR_e_VTVROptToDepVars_Value: accessed-variable=VaTSXR_e_VTVROptToDepVars.Value
              OUT_VaTSXR_b_VTVROptToConstrnChk_Value: accessed-variable=VaTSXR_b_VTVROptToConstrnChk.Value
              OUT_VeTSXR_e_VTVROptToConstrnType_Value: accessed-variable=VeTSXR_e_VTVROptToConstrnType.Value
              OUT_VeTSXR_e_VTVROptToConstrnEqltyEqn_Value: accessed-variable=VeTSXR_e_VTVROptToConstrnEqltyEqn.Value
              OUT_VaTSXR_r_VTVRTacToConstrn_Value: accessed-variable=VaTSXR_r_VTVRTacToConstrn.Value
              OUT_VaTSXR_e_VTVRTacToDepVars_Value: accessed-variable=VaTSXR_e_VTVRTacToDepVars.Value
              OUT_VaTSXR_b_VTVRTacToConstrnChk_Value: accessed-variable=VaTSXR_b_VTVRTacToConstrnChk.Value
              OUT_VaTSXR_e_VTVRTacToConstrnPrfrdComb_Value: accessed-variable=VaTSXR_e_VTVRTacToConstrnPrfrdComb.Value
              OUT_VeTSXR_r_TturbFromTof_Value: accessed-variable=VeTSXR_r_TturbFromTof.Value
              OUT_VaTSXR_r_OITROptTiConstrn_Value: accessed-variable=VaTSXR_r_OITROptTiConstrn.Value
              OUT_VaTSXR_e_OITROptTiDepVars_Value: accessed-variable=VaTSXR_e_OITROptTiDepVars.Value
              OUT_VaTSXR_b_OITROptTiConstrnChk_Value: accessed-variable=VaTSXR_b_OITROptTiConstrnChk.Value
              OUT_VeTSXR_e_OITROptTiConstrnType_Value: accessed-variable=VeTSXR_e_OITROptTiConstrnType.Value
              OUT_VeTSXR_e_OITROptTiConstrnEqltyEqn_Value: accessed-variable=VeTSXR_e_OITROptTiConstrnEqltyEqn.Value
              OUT_VaTSXR_r_OITRTacToConstrn_Value: accessed-variable=VaTSXR_r_OITRTacToConstrn.Value
              OUT_VaTSXR_e_OITRTacToDepVars_Value: accessed-variable=VaTSXR_e_OITRTacToDepVars.Value
              OUT_VaTSXR_b_OITRTacToConstrnChk_Value: accessed-variable=VaTSXR_b_OITRTacToConstrnChk.Value
              OUT_VaTSXR_e_OITRTacToConstrnPrfrdComb_Value: accessed-variable=VaTSXR_e_OITRTacToConstrnPrfrdComb.Value
              OUT_VaTSXR_r_OITRTacTiConstrn_Value: accessed-variable=VaTSXR_r_OITRTacTiConstrn.Value
              OUT_VaTSXR_e_OITRTacTiDepVars_Value: accessed-variable=VaTSXR_e_OITRTacTiDepVars.Value
              OUT_VaTSXR_b_OITRTacTiConstrnChk_Value: accessed-variable=VaTSXR_b_OITRTacTiConstrnChk.Value
              OUT_VaTSXR_e_OITRTacTiConstrnPrfrdComb_Value: accessed-variable=VaTSXR_e_OITRTacTiConstrnPrfrdComb.Value
              OUT_VaTSXR_r_OITROptTiPredConstrn_Value: accessed-variable=VaTSXR_r_OITROptTiPredConstrn.Value
              OUT_VaTSXR_e_OITROptTiPredDepVars_Value: accessed-variable=VaTSXR_e_OITROptTiPredDepVars.Value
              OUT_VaTSXR_b_OITROptTiPredConstrnChk_Value: accessed-variable=VaTSXR_b_OITROptTiPredConstrnChk.Value
              OUT_VeTSXR_e_OITROptTiPredConstrnType_Value: accessed-variable=VeTSXR_e_OITROptTiPredConstrnType.Value
              OUT_VeTSXR_e_OITROptTiPredConstrnEqltyEqn_Value: accessed-variable=VeTSXR_e_OITROptTiPredConstrnEqltyEqn.Value
              OUT_VaTSXR_r_OITRTacToPredConstrn_Value: accessed-variable=VaTSXR_r_OITRTacToPredConstrn.Value
              OUT_VaTSXR_e_OITRTacToPredDepVars_Value: accessed-variable=VaTSXR_e_OITRTacToPredDepVars.Value
              OUT_VaTSXR_b_OITRTacToPredConstrnChk_Value: accessed-variable=VaTSXR_b_OITRTacToPredConstrnChk.Value
              OUT_VaTSXR_e_OITRTacToPredConstrnPrfrdComb_Value: accessed-variable=VaTSXR_e_OITRTacToPredConstrnPrfrdComb.Value
              OUT_VaTSXR_r_HTDRToConstrn_Value: accessed-variable=VaTSXR_r_HTDRToConstrn.Value
              OUT_VaTSXR_e_HTDRToDepVars_Value: accessed-variable=VaTSXR_e_HTDRToDepVars.Value
              OUT_VaTSXR_b_HTDRToConstrnChk_Value: accessed-variable=VaTSXR_b_HTDRToConstrnChk.Value
              OUT_VeTSXR_e_HTDRToConstrnType_Value: accessed-variable=VeTSXR_e_HTDRToConstrnType.Value
              OUT_VeTSXR_e_HTDRToConstrnEqltyEqn_Value: accessed-variable=VeTSXR_e_HTDRToConstrnEqltyEqn.Value
              OUT_VaTSXR_r_HTDRTacTiConstrn_Value: accessed-variable=VaTSXR_r_HTDRTacTiConstrn.Value
              OUT_VeTSXR_e_HTDRTacTiConstrnType_Value: accessed-variable=VeTSXR_e_HTDRTacTiConstrnType.Value
              OUT_VaTSXR_r_STRRToConstrn_Value: accessed-variable=VaTSXR_r_STRRToConstrn.Value
              OUT_VaTSXR_e_STRRToDepVars_Value: accessed-variable=VaTSXR_e_STRRToDepVars.Value
              OUT_VaTSXR_b_STRRToConstrnChk_Value: accessed-variable=VaTSXR_b_STRRToConstrnChk.Value
              OUT_VeTSXR_e_STRRToConstrnType_Value: accessed-variable=VeTSXR_e_STRRToConstrnType.Value
              OUT_VeTSXR_e_STRRToConstrnEqltyEqn_Value: accessed-variable=VeTSXR_e_STRRToConstrnEqltyEqn.Value
              OUT_VaTSXR_r_HSERNidotConstrn_Value: accessed-variable=VaTSXR_r_HSERNidotConstrn.Value
              OUT_VaTSXR_e_HSERNidotDepVars_Value: accessed-variable=VaTSXR_e_HSERNidotDepVars.Value
              OUT_VaTSXR_b_HSERNidotConstrnChk_Value: accessed-variable=VaTSXR_b_HSERNidotConstrnChk.Value
              OUT_VaTSXR_e_HSERNidotConstrnPrfrdComb_Value: accessed-variable=VaTSXR_e_HSERNidotConstrnPrfrdComb.Value
              OUT_VaTSXR_r_HSERNxDotCnstrnt_Value: accessed-variable=VaTSXR_r_HSERNxDotCnstrnt.Value
              OUT_VaTSXR_e_HSERNxDotDepVars_Value: accessed-variable=VaTSXR_e_HSERNxDotDepVars.Value
              OUT_VaTSXR_b_HSERNxDotChk_Value: accessed-variable=VaTSXR_b_HSERNxDotChk.Value
              OUT_VaTSXR_e_HSERNxdotConstrnPrfrdComb_Value: accessed-variable=VaTSXR_e_HSERNxdotConstrnPrfrdComb.Value
              OUT_VaTSXR_r_HSERTcyFromTcxAndTi_TaTbDep_Value: accessed-variable=VaTSXR_r_HSERTcyFromTcxAndTi_TaTbDep.Value
              OUT_VaTSXR_r_AXLRCalcToEqn_Value: accessed-variable=VaTSXR_r_AXLRCalcToEqn.Value
              OUT_VaTSXR_r_TITRCalcTiEqn_Value: accessed-variable=VaTSXR_r_TITRCalcTiEqn.Value
              OUT_VaTSXR_r_HSERNiMat_Value: accessed-variable=VaTSXR_r_HSERNiMat.Value
              OUT_VaTSXR_b_HSERNiMatChk_Value: accessed-variable=VaTSXR_b_HSERNiMatChk.Value
              OUT_VaTSXR_b_HSERNiMatActSpdFlag_Value: accessed-variable=VaTSXR_b_HSERNiMatActSpdFlag.Value
              OUT_VaTSXR_r_HSERNoMat_Value: accessed-variable=VaTSXR_r_HSERNoMat.Value
              OUT_VaTSXR_b_HSERNoMatChk_Value: accessed-variable=VaTSXR_b_HSERNoMatChk.Value
              OUT_VaTSXR_b_HSERNoMatActSpdFlag_Value: accessed-variable=VaTSXR_b_HSERNoMatActSpdFlag.Value
              OUT_VaTSXR_r_STDRMotSpdMat_NmDep_Value: accessed-variable=VaTSXR_r_STDRMotSpdMat_NmDep.Value
              OUT_VaTSXR_r_OITRMotSpdMat_NmDep_Value: accessed-variable=VaTSXR_r_OITRMotSpdMat_NmDep.Value
              OUT_VaTSXR_r_VTVRMotSpdMat_NmDep_Value: accessed-variable=VaTSXR_r_VTVRMotSpdMat_NmDep.Value
              OUT_VaTSXR_r_M_CalcTCxEqn_Value: accessed-variable=VaTSXR_r_M_CalcTCxEqn.Value
              OUT_VaTSXR_r_CalcTlfEqn_Value: accessed-variable=VaTSXR_r_CalcTlfEqn.Value
              OUT_VaTSXR_r_HSERNxMat_Value: accessed-variable=VaTSXR_r_HSERNxMat.Value
              OUT_VaTSXR_b_HSERNxMatChk_Value: accessed-variable=VaTSXR_b_HSERNxMatChk.Value
              OUT_VaTSXR_b_HSERNxMatActSpdFlag_Value: accessed-variable=VaTSXR_b_HSERNxMatActSpdFlag.Value
              OUT_VaTSXR_r_HSERNxNc1IndDep_Value: accessed-variable=VaTSXR_r_HSERNxNc1IndDep.Value
              OUT_VaTSXR_r_HSERNxNc2IndDep_Value: accessed-variable=VaTSXR_r_HSERNxNc2IndDep.Value
              OUT_VaTSXR_r_HSERNxNMtrIndDep_Value: accessed-variable=VaTSXR_r_HSERNxNMtrIndDep.Value
              OUT_VeTSXR_r_NoDot2NxDot_Value: accessed-variable=VeTSXR_r_NoDot2NxDot.Value
              OUT_VeTSXR_e_VTVRTacToConstrnCombEqn_Value: accessed-variable=VeTSXR_e_VTVRTacToConstrnCombEqn.Value
              OUT_VeTSXR_e_OITRTacTiConstrnCombEqn_Value: accessed-variable=VeTSXR_e_OITRTacTiConstrnCombEqn.Value
              OUT_VeTSXR_e_HSERNidotConstrnCombEqn_Value: accessed-variable=VeTSXR_e_HSERNidotConstrnCombEqn.Value
              OUT_VeTSXR_e_OITRTacToPredConstrnCombEqn_Value: accessed-variable=VeTSXR_e_OITRTacToPredConstrnCombEqn.Value
              OUT_VeTSXR_e_OITRTacToConstrnCombEqn_Value: accessed-variable=VeTSXR_e_OITRTacToConstrnCombEqn.Value
              OUT_VeTSXR_e_HSERNxdotConstrnCombEqn_Value: accessed-variable=VeTSXR_e_HSERNxdotConstrnCombEqn.Value
              OUT_VaTSXR_r_AXLRCalcTofEqn_Value: accessed-variable=VaTSXR_r_AXLRCalcTofEqn.Value
              OUT_VaTSXR_r_AXLRCalcTorEqn_Value: accessed-variable=VaTSXR_r_AXLRCalcTorEqn.Value
              OUT_VaTSXR_b_VTVRToConstrnPalChk_Value: accessed-variable=VaTSXR_b_VTVRToConstrnPalChk.Value
              OUT_VaTSXR_b_OITRTacToPredConstrnPalChk_Value: accessed-variable=VaTSXR_b_OITRTacToPredConstrnPalChk.Value
              OUT_VaTSXR_b_OITRTacToConstrnPalChk_Value: accessed-variable=VaTSXR_b_OITRTacToConstrnPalChk.Value
              OUT_VaTSXR_b_OITRTacTiConstrnPalChk_Value: accessed-variable=VaTSXR_b_OITRTacTiConstrnPalChk.Value
              OUT_VaTSXR_b_HTDRTacTiConstrnPalChk_Value: accessed-variable=VaTSXR_b_HTDRTacTiConstrnPalChk.Value
              OUT_VaTSXR_b_HSERNidotConstrnPalChk_Value: accessed-variable=VaTSXR_b_HSERNidotConstrnPalChk.Value
              OUT_VaTSXR_b_HSERNxdotConstrnPalChk_Value: accessed-variable=VaTSXR_b_HSERNxdotConstrnPalChk.Value
              OUT_VaTSXR_r_OITRTacTiPredConstrn_Value: accessed-variable=VaTSXR_r_OITRTacTiPredConstrn.Value
              OUT_VaTSXR_e_OITRTacTiPredDepVars_Value: accessed-variable=VaTSXR_e_OITRTacTiPredDepVars.Value
              OUT_VaTSXR_b_OITRTacTiPredConstrnChk_Value: accessed-variable=VaTSXR_b_OITRTacTiPredConstrnChk.Value
              OUT_VaTSXR_e_OITRTacTiPredConstrnPrfrdComb_Value: accessed-variable=VaTSXR_e_OITRTacTiPredConstrnPrfrdComb.Value
              OUT_VeTSXR_e_OITRTacTiPredConstrnCombEqn_Value: accessed-variable=VeTSXR_e_OITRTacTiPredConstrnCombEqn.Value
              OUT_VaTSXR_b_OITRTacTiPredConstrnPalChk_Value: accessed-variable=VaTSXR_b_OITRTacTiPredConstrnPalChk.Value
          10 x parameter access:
            CALPRM_KeTSXR_D_Ba_KeTSXR_D_Ba: accessed-parameter=KeTSXR_D_Ba.KeTSXR_D_Ba
            CALPRM_KeTSXR_D_Bb_KeTSXR_D_Bb: accessed-parameter=KeTSXR_D_Bb.KeTSXR_D_Bb
            CALPRM_KeTSXR_D_Be_KeTSXR_D_Be: accessed-parameter=KeTSXR_D_Be.KeTSXR_D_Be
            CALPRM_KeTSXR_J_Ia_KeTSXR_J_Ia: accessed-parameter=KeTSXR_J_Ia.KeTSXR_J_Ia
            CALPRM_KeTSXR_J_Ib_KeTSXR_J_Ib: accessed-parameter=KeTSXR_J_Ib.KeTSXR_J_Ib
            CALPRM_KeTSXR_J_Ie_KeTSXR_J_Ie: accessed-parameter=KeTSXR_J_Ie.KeTSXR_J_Ie
            CALPRM_KeTSXR_r_FDRf_KeTSXR_r_FDRf: accessed-parameter=KeTSXR_r_FDRf.KeTSXR_r_FDRf
            CALPRM_KeTSXR_r_FDRr_KeTSXR_r_FDRr: accessed-parameter=KeTSXR_r_FDRr.KeTSXR_r_FDRr
            CALPRM_KeTSXR_r_P1f_KeTSXR_r_P1f: accessed-parameter=KeTSXR_r_P1f.KeTSXR_r_P1f
            CALPRM_KeTSXR_r_P2p5_KeTSXR_r_P2p5: accessed-parameter=KeTSXR_r_P2p5.KeTSXR_r_P2p5
        TSXR_PwrOn
          data-send-points:
            99 x access:
              OUT_VaTSXR_r_VTVROptToConstrn_Value: accessed-variable=VaTSXR_r_VTVROptToConstrn.Value
              OUT_VaTSXR_e_VTVROptToDepVars_Value: accessed-variable=VaTSXR_e_VTVROptToDepVars.Value
              OUT_VaTSXR_b_VTVROptToConstrnChk_Value: accessed-variable=VaTSXR_b_VTVROptToConstrnChk.Value
              OUT_VeTSXR_e_VTVROptToConstrnType_Value: accessed-variable=VeTSXR_e_VTVROptToConstrnType.Value
              OUT_VeTSXR_e_VTVROptToConstrnEqltyEqn_Value: accessed-variable=VeTSXR_e_VTVROptToConstrnEqltyEqn.Value
              OUT_VaTSXR_r_VTVRTacToConstrn_Value: accessed-variable=VaTSXR_r_VTVRTacToConstrn.Value
              OUT_VaTSXR_e_VTVRTacToDepVars_Value: accessed-variable=VaTSXR_e_VTVRTacToDepVars.Value
              OUT_VaTSXR_b_VTVRTacToConstrnChk_Value: accessed-variable=VaTSXR_b_VTVRTacToConstrnChk.Value
              OUT_VaTSXR_e_VTVRTacToConstrnPrfrdComb_Value: accessed-variable=VaTSXR_e_VTVRTacToConstrnPrfrdComb.Value
              OUT_VeTSXR_r_TturbFromTof_Value: accessed-variable=VeTSXR_r_TturbFromTof.Value
              OUT_VaTSXR_r_OITROptTiConstrn_Value: accessed-variable=VaTSXR_r_OITROptTiConstrn.Value
              OUT_VaTSXR_e_OITROptTiDepVars_Value: accessed-variable=VaTSXR_e_OITROptTiDepVars.Value
              OUT_VaTSXR_b_OITROptTiConstrnChk_Value: accessed-variable=VaTSXR_b_OITROptTiConstrnChk.Value
              OUT_VeTSXR_e_OITROptTiConstrnType_Value: accessed-variable=VeTSXR_e_OITROptTiConstrnType.Value
              OUT_VeTSXR_e_OITROptTiConstrnEqltyEqn_Value: accessed-variable=VeTSXR_e_OITROptTiConstrnEqltyEqn.Value
              OUT_VaTSXR_r_OITRTacToConstrn_Value: accessed-variable=VaTSXR_r_OITRTacToConstrn.Value
              OUT_VaTSXR_e_OITRTacToDepVars_Value: accessed-variable=VaTSXR_e_OITRTacToDepVars.Value
              OUT_VaTSXR_b_OITRTacToConstrnChk_Value: accessed-variable=VaTSXR_b_OITRTacToConstrnChk.Value
              OUT_VaTSXR_e_OITRTacToConstrnPrfrdComb_Value: accessed-variable=VaTSXR_e_OITRTacToConstrnPrfrdComb.Value
              OUT_VaTSXR_r_OITRTacTiConstrn_Value: accessed-variable=VaTSXR_r_OITRTacTiConstrn.Value
              OUT_VaTSXR_e_OITRTacTiDepVars_Value: accessed-variable=VaTSXR_e_OITRTacTiDepVars.Value
              OUT_VaTSXR_b_OITRTacTiConstrnChk_Value: accessed-variable=VaTSXR_b_OITRTacTiConstrnChk.Value
              OUT_VaTSXR_e_OITRTacTiConstrnPrfrdComb_Value: accessed-variable=VaTSXR_e_OITRTacTiConstrnPrfrdComb.Value
              OUT_VaTSXR_r_OITROptTiPredConstrn_Value: accessed-variable=VaTSXR_r_OITROptTiPredConstrn.Value
              OUT_VaTSXR_e_OITROptTiPredDepVars_Value: accessed-variable=VaTSXR_e_OITROptTiPredDepVars.Value
              OUT_VaTSXR_b_OITROptTiPredConstrnChk_Value: accessed-variable=VaTSXR_b_OITROptTiPredConstrnChk.Value
              OUT_VeTSXR_e_OITROptTiPredConstrnType_Value: accessed-variable=VeTSXR_e_OITROptTiPredConstrnType.Value
              OUT_VeTSXR_e_OITROptTiPredConstrnEqltyEqn_Value: accessed-variable=VeTSXR_e_OITROptTiPredConstrnEqltyEqn.Value
              OUT_VaTSXR_r_OITRTacToPredConstrn_Value: accessed-variable=VaTSXR_r_OITRTacToPredConstrn.Value
              OUT_VaTSXR_e_OITRTacToPredDepVars_Value: accessed-variable=VaTSXR_e_OITRTacToPredDepVars.Value
              OUT_VaTSXR_b_OITRTacToPredConstrnChk_Value: accessed-variable=VaTSXR_b_OITRTacToPredConstrnChk.Value
              OUT_VaTSXR_e_OITRTacToPredConstrnPrfrdComb_Value: accessed-variable=VaTSXR_e_OITRTacToPredConstrnPrfrdComb.Value
              OUT_VaTSXR_r_HTDRToConstrn_Value: accessed-variable=VaTSXR_r_HTDRToConstrn.Value
              OUT_VaTSXR_e_HTDRToDepVars_Value: accessed-variable=VaTSXR_e_HTDRToDepVars.Value
              OUT_VaTSXR_b_HTDRToConstrnChk_Value: accessed-variable=VaTSXR_b_HTDRToConstrnChk.Value
              OUT_VeTSXR_e_HTDRToConstrnType_Value: accessed-variable=VeTSXR_e_HTDRToConstrnType.Value
              OUT_VeTSXR_e_HTDRToConstrnEqltyEqn_Value: accessed-variable=VeTSXR_e_HTDRToConstrnEqltyEqn.Value
              OUT_VaTSXR_r_HTDRTacTiConstrn_Value: accessed-variable=VaTSXR_r_HTDRTacTiConstrn.Value
              OUT_VeTSXR_e_HTDRTacTiConstrnType_Value: accessed-variable=VeTSXR_e_HTDRTacTiConstrnType.Value
              OUT_VaTSXR_r_STRRToConstrn_Value: accessed-variable=VaTSXR_r_STRRToConstrn.Value
              OUT_VaTSXR_e_STRRToDepVars_Value: accessed-variable=VaTSXR_e_STRRToDepVars.Value
              OUT_VaTSXR_b_STRRToConstrnChk_Value: accessed-variable=VaTSXR_b_STRRToConstrnChk.Value
              OUT_VeTSXR_e_STRRToConstrnType_Value: accessed-variable=VeTSXR_e_STRRToConstrnType.Value
              OUT_VeTSXR_e_STRRToConstrnEqltyEqn_Value: accessed-variable=VeTSXR_e_STRRToConstrnEqltyEqn.Value
              OUT_VaTSXR_r_HSERNidotConstrn_Value: accessed-variable=VaTSXR_r_HSERNidotConstrn.Value
              OUT_VaTSXR_e_HSERNidotDepVars_Value: accessed-variable=VaTSXR_e_HSERNidotDepVars.Value
              OUT_VaTSXR_b_HSERNidotConstrnChk_Value: accessed-variable=VaTSXR_b_HSERNidotConstrnChk.Value
              OUT_VaTSXR_e_HSERNidotConstrnPrfrdComb_Value: accessed-variable=VaTSXR_e_HSERNidotConstrnPrfrdComb.Value
              OUT_VaTSXR_r_HSERNxDotCnstrnt_Value: accessed-variable=VaTSXR_r_HSERNxDotCnstrnt.Value
              OUT_VaTSXR_e_HSERNxDotDepVars_Value: accessed-variable=VaTSXR_e_HSERNxDotDepVars.Value
              OUT_VaTSXR_b_HSERNxDotChk_Value: accessed-variable=VaTSXR_b_HSERNxDotChk.Value
              OUT_VaTSXR_e_HSERNxdotConstrnPrfrdComb_Value: accessed-variable=VaTSXR_e_HSERNxdotConstrnPrfrdComb.Value
              OUT_VaTSXR_r_HSERTcyFromTcxAndTi_TaTbDep_Value: accessed-variable=VaTSXR_r_HSERTcyFromTcxAndTi_TaTbDep.Value
              OUT_VaTSXR_r_AXLRCalcToEqn_Value: accessed-variable=VaTSXR_r_AXLRCalcToEqn.Value
              OUT_VaTSXR_r_TITRCalcTiEqn_Value: accessed-variable=VaTSXR_r_TITRCalcTiEqn.Value
              OUT_VaTSXR_r_HSERNiMat_Value: accessed-variable=VaTSXR_r_HSERNiMat.Value
              OUT_VaTSXR_b_HSERNiMatChk_Value: accessed-variable=VaTSXR_b_HSERNiMatChk.Value
              OUT_VaTSXR_b_HSERNiMatActSpdFlag_Value: accessed-variable=VaTSXR_b_HSERNiMatActSpdFlag.Value
              OUT_VaTSXR_r_HSERNoMat_Value: accessed-variable=VaTSXR_r_HSERNoMat.Value
              OUT_VaTSXR_b_HSERNoMatChk_Value: accessed-variable=VaTSXR_b_HSERNoMatChk.Value
              OUT_VaTSXR_b_HSERNoMatActSpdFlag_Value: accessed-variable=VaTSXR_b_HSERNoMatActSpdFlag.Value
              OUT_VaTSXR_r_STDRMotSpdMat_NmDep_Value: accessed-variable=VaTSXR_r_STDRMotSpdMat_NmDep.Value
              OUT_VaTSXR_r_OITRMotSpdMat_NmDep_Value: accessed-variable=VaTSXR_r_OITRMotSpdMat_NmDep.Value
              OUT_VaTSXR_r_VTVRMotSpdMat_NmDep_Value: accessed-variable=VaTSXR_r_VTVRMotSpdMat_NmDep.Value
              OUT_VaTSXR_r_N_ClchSlpMat_NcnDep_Value: accessed-variable=VaTSXR_r_N_ClchSlpMat_NcnDep.Value
              OUT_VaTSXR_r_M1_ClchSlpMat_NcnDep_Value: accessed-variable=VaTSXR_r_M1_ClchSlpMat_NcnDep.Value
              OUT_VaTSXR_r_M2_ClchSlpMat_NcnDep_Value: accessed-variable=VaTSXR_r_M2_ClchSlpMat_NcnDep.Value
              OUT_VaTSXR_r_GearRatios_Value: accessed-variable=VaTSXR_r_GearRatios.Value
              OUT_VaTSXR_r_M_CalcTCxEqn_Value: accessed-variable=VaTSXR_r_M_CalcTCxEqn.Value
              OUT_VaTSXR_r_CalcTlfEqn_Value: accessed-variable=VaTSXR_r_CalcTlfEqn.Value
              OUT_VaTSXR_r_STRRNxMat_NcnDep_Value: accessed-variable=VaTSXR_r_STRRNxMat_NcnDep.Value
              OUT_VaTSXR_r_HSERNxMat_Value: accessed-variable=VaTSXR_r_HSERNxMat.Value
              OUT_VaTSXR_b_HSERNxMatChk_Value: accessed-variable=VaTSXR_b_HSERNxMatChk.Value
              OUT_VaTSXR_b_HSERNxMatActSpdFlag_Value: accessed-variable=VaTSXR_b_HSERNxMatActSpdFlag.Value
              OUT_VaTSXR_r_HSERNxNc1IndDep_Value: accessed-variable=VaTSXR_r_HSERNxNc1IndDep.Value
              OUT_VaTSXR_r_HSERNxNc2IndDep_Value: accessed-variable=VaTSXR_r_HSERNxNc2IndDep.Value
              OUT_VaTSXR_r_HSERNxNMtrIndDep_Value: accessed-variable=VaTSXR_r_HSERNxNMtrIndDep.Value
              OUT_VeTSXR_r_NoDot2NxDot_Value: accessed-variable=VeTSXR_r_NoDot2NxDot.Value
              OUT_VeTSXR_e_VTVRTacToConstrnCombEqn_Value: accessed-variable=VeTSXR_e_VTVRTacToConstrnCombEqn.Value
              OUT_VeTSXR_e_OITRTacTiConstrnCombEqn_Value: accessed-variable=VeTSXR_e_OITRTacTiConstrnCombEqn.Value
              OUT_VeTSXR_e_HSERNidotConstrnCombEqn_Value: accessed-variable=VeTSXR_e_HSERNidotConstrnCombEqn.Value
              OUT_VeTSXR_e_OITRTacToPredConstrnCombEqn_Value: accessed-variable=VeTSXR_e_OITRTacToPredConstrnCombEqn.Value
              OUT_VeTSXR_e_OITRTacToConstrnCombEqn_Value: accessed-variable=VeTSXR_e_OITRTacToConstrnCombEqn.Value
              OUT_VeTSXR_e_HSERNxdotConstrnCombEqn_Value: accessed-variable=VeTSXR_e_HSERNxdotConstrnCombEqn.Value
              OUT_VaTSXR_r_AXLRCalcTofEqn_Value: accessed-variable=VaTSXR_r_AXLRCalcTofEqn.Value
              OUT_VaTSXR_r_AXLRCalcTorEqn_Value: accessed-variable=VaTSXR_r_AXLRCalcTorEqn.Value
              OUT_VaTSXR_b_VTVRToConstrnPalChk_Value: accessed-variable=VaTSXR_b_VTVRToConstrnPalChk.Value
              OUT_VaTSXR_b_OITRTacToPredConstrnPalChk_Value: accessed-variable=VaTSXR_b_OITRTacToPredConstrnPalChk.Value
              OUT_VaTSXR_b_OITRTacToConstrnPalChk_Value: accessed-variable=VaTSXR_b_OITRTacToConstrnPalChk.Value
              OUT_VaTSXR_b_OITRTacTiConstrnPalChk_Value: accessed-variable=VaTSXR_b_OITRTacTiConstrnPalChk.Value
              OUT_VaTSXR_b_HTDRTacTiConstrnPalChk_Value: accessed-variable=VaTSXR_b_HTDRTacTiConstrnPalChk.Value
              OUT_VaTSXR_b_HSERNidotConstrnPalChk_Value: accessed-variable=VaTSXR_b_HSERNidotConstrnPalChk.Value
              OUT_VaTSXR_b_HSERNxdotConstrnPalChk_Value: accessed-variable=VaTSXR_b_HSERNxdotConstrnPalChk.Value
              OUT_VaTSXR_r_OITRTacTiPredConstrn_Value: accessed-variable=VaTSXR_r_OITRTacTiPredConstrn.Value
              OUT_VaTSXR_e_OITRTacTiPredDepVars_Value: accessed-variable=VaTSXR_e_OITRTacTiPredDepVars.Value
              OUT_VaTSXR_b_OITRTacTiPredConstrnChk_Value: accessed-variable=VaTSXR_b_OITRTacTiPredConstrnChk.Value
              OUT_VaTSXR_e_OITRTacTiPredConstrnPrfrdComb_Value: accessed-variable=VaTSXR_e_OITRTacTiPredConstrnPrfrdComb.Value
              OUT_VeTSXR_e_OITRTacTiPredConstrnCombEqn_Value: accessed-variable=VeTSXR_e_OITRTacTiPredConstrnCombEqn.Value
              OUT_VaTSXR_b_OITRTacTiPredConstrnPalChk_Value: accessed-variable=VaTSXR_b_OITRTacTiPredConstrnPalChk.Value
      12 x variation point proxy, all with category=CONDITION:
        Variant_TSXR_10: condition-access=0
        Variant_TSXR_3: condition-access=0
        Variant_TSXR_4: condition-access=1
        Variant_TSXR_5: condition-access=0
        Variant_TSXR_6: condition-access=0
        Variant_TSXR_7: condition-access=1
        Variant_TSXR_8: condition-access=0
        Variant_TSXR_9: condition-access=0
        Variant_TSXR_BEV2SpdSym: condition-access=0
        Variant_TSXR_OtherNum: condition-access=1
        Variant_TSXR_P1P2p5Sym: condition-access=0
        Variant_TSXR_P1P4Sym: condition-access=0
